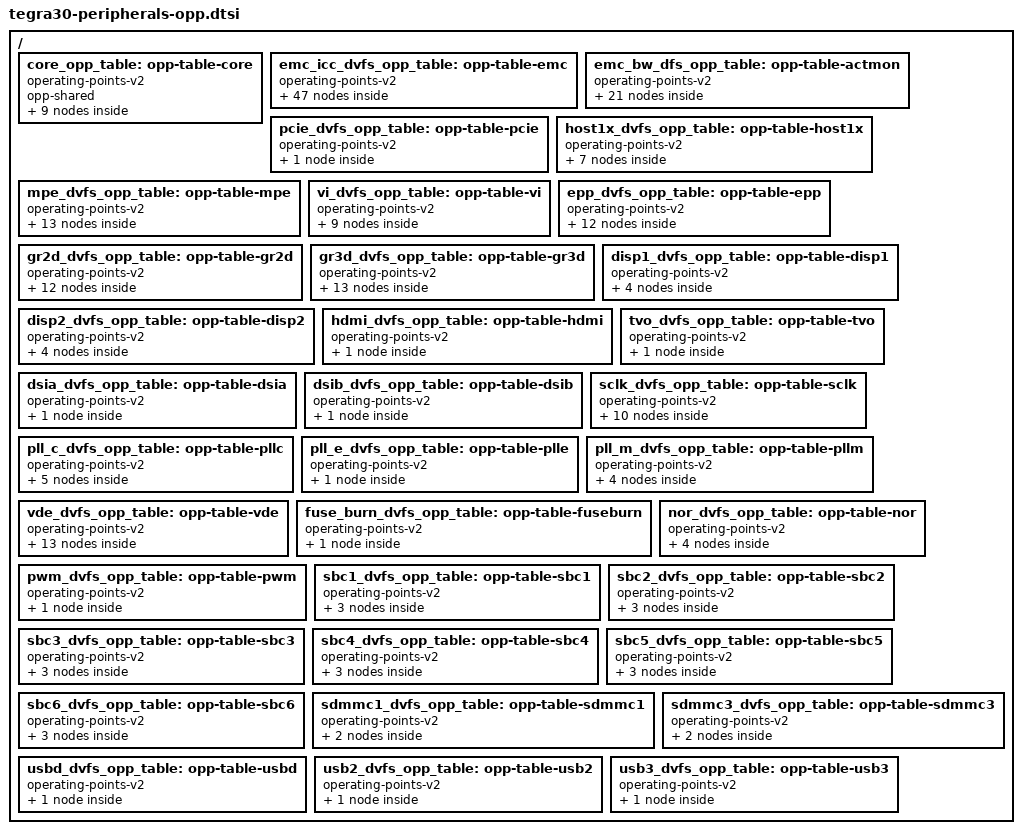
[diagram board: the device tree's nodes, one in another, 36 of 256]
// SPDX-License-Identifier: GPL-2.0

/ {
	core_opp_table: opp-table-core {
		compatible = "operating-points-v2";
		opp-shared;

		core_opp_950: opp-950000 {
			opp-microvolt = <950000 950000 1350000>;
			opp-level = <950000>;
		};

		core_opp_1000: opp-1000000 {
			opp-microvolt = <1000000 1000000 1350000>;
			opp-level = <1000000>;
		};

		core_opp_1050: opp-1050000 {
			opp-microvolt = <1050000 1050000 1350000>;
			opp-level = <1050000>;
		};

		core_opp_1100: opp-1100000 {
			opp-microvolt = <1100000 1100000 1350000>;
			opp-level = <1100000>;
		};

		core_opp_1150: opp-1150000 {
			opp-microvolt = <1150000 1150000 1350000>;
			opp-level = <1150000>;
		};

		core_opp_1200: opp-1200000 {
			opp-microvolt = <1200000 1200000 1350000>;
			opp-level = <1200000>;
		};

		core_opp_1250: opp-1250000 {
			opp-microvolt = <1250000 1250000 1350000>;
			opp-level = <1250000>;
		};

		core_opp_1300: opp-1300000 {
			opp-microvolt = <1300000 1300000 1350000>;
			opp-level = <1300000>;
		};

		core_opp_1350: opp-1350000 {
			opp-microvolt = <1350000 1350000 1350000>;
			opp-level = <1350000>;
		};
	};

	emc_icc_dvfs_opp_table: opp-table-emc {
		compatible = "operating-points-v2";

		opp-12750000-950 {
			opp-microvolt = <950000 950000 1350000>;
			opp-hz = /bits/ 64 <12750000>;
			opp-supported-hw = <0x0006>;
			required-opps = <&core_opp_950>;
		};

		opp-12750000-1000 {
			opp-microvolt = <1000000 1000000 1350000>;
			opp-hz = /bits/ 64 <12750000>;
			opp-supported-hw = <0x0001>;
			required-opps = <&core_opp_1000>;
		};

		opp-12750000-1250 {
			opp-microvolt = <1250000 1250000 1350000>;
			opp-hz = /bits/ 64 <12750000>;
			opp-supported-hw = <0x0008>;
			required-opps = <&core_opp_1250>;
		};

		opp-25500000-950 {
			opp-microvolt = <950000 950000 1350000>;
			opp-hz = /bits/ 64 <25500000>;
			opp-supported-hw = <0x0006>;
			required-opps = <&core_opp_950>;
		};

		opp-25500000-1000 {
			opp-microvolt = <1000000 1000000 1350000>;
			opp-hz = /bits/ 64 <25500000>;
			opp-supported-hw = <0x0001>;
			required-opps = <&core_opp_1000>;
		};

		opp-25500000-1250 {
			opp-microvolt = <1250000 1250000 1350000>;
			opp-hz = /bits/ 64 <25500000>;
			opp-supported-hw = <0x0008>;
			required-opps = <&core_opp_1250>;
		};

		opp-27000000-950 {
			opp-microvolt = <950000 950000 1350000>;
			opp-hz = /bits/ 64 <27000000>;
			opp-supported-hw = <0x0006>;
			required-opps = <&core_opp_950>;
		};

		opp-27000000-1000 {
			opp-microvolt = <1000000 1000000 1350000>;
			opp-hz = /bits/ 64 <27000000>;
			opp-supported-hw = <0x0001>;
			required-opps = <&core_opp_1000>;
		};

		opp-27000000-1250 {
			opp-microvolt = <1250000 1250000 1350000>;
			opp-hz = /bits/ 64 <27000000>;
			opp-supported-hw = <0x0008>;
			required-opps = <&core_opp_1250>;
		};

		opp-51000000-950 {
			opp-microvolt = <950000 950000 1350000>;
			opp-hz = /bits/ 64 <51000000>;
			opp-supported-hw = <0x0006>;
			required-opps = <&core_opp_950>;
		};

		opp-51000000-1000 {
			opp-microvolt = <1000000 1000000 1350000>;
			opp-hz = /bits/ 64 <51000000>;
			opp-supported-hw = <0x0001>;
			required-opps = <&core_opp_1000>;
		};

		opp-51000000-1250 {
			opp-microvolt = <1250000 1250000 1350000>;
			opp-hz = /bits/ 64 <51000000>;
			opp-supported-hw = <0x0008>;
			required-opps = <&core_opp_1250>;
		};

		opp-54000000-950 {
			opp-microvolt = <950000 950000 1350000>;
			opp-hz = /bits/ 64 <54000000>;
			opp-supported-hw = <0x0006>;
			required-opps = <&core_opp_950>;
		};

		opp-54000000-1000 {
			opp-microvolt = <1000000 1000000 1350000>;
			opp-hz = /bits/ 64 <54000000>;
			opp-supported-hw = <0x0001>;
			required-opps = <&core_opp_1000>;
		};

		opp-54000000-1250 {
			opp-microvolt = <1250000 1250000 1350000>;
			opp-hz = /bits/ 64 <54000000>;
			opp-supported-hw = <0x0008>;
			required-opps = <&core_opp_1250>;
		};

		opp-102000000-950 {
			opp-microvolt = <950000 950000 1350000>;
			opp-hz = /bits/ 64 <102000000>;
			opp-supported-hw = <0x0006>;
			required-opps = <&core_opp_950>;
		};

		opp-102000000-1000 {
			opp-microvolt = <1000000 1000000 1350000>;
			opp-hz = /bits/ 64 <102000000>;
			opp-supported-hw = <0x0001>;
			required-opps = <&core_opp_1000>;
		};

		opp-102000000-1250 {
			opp-microvolt = <1250000 1250000 1350000>;
			opp-hz = /bits/ 64 <102000000>;
			opp-supported-hw = <0x0008>;
			required-opps = <&core_opp_1250>;
		};

		opp-108000000-1000 {
			opp-microvolt = <1000000 1000000 1350000>;
			opp-hz = /bits/ 64 <108000000>;
			opp-supported-hw = <0x0007>;
			required-opps = <&core_opp_1000>;
		};

		opp-108000000-1250 {
			opp-microvolt = <1250000 1250000 1350000>;
			opp-hz = /bits/ 64 <108000000>;
			opp-supported-hw = <0x0008>;
			required-opps = <&core_opp_1250>;
		};

		opp-204000000-1000 {
			opp-microvolt = <1000000 1000000 1350000>;
			opp-hz = /bits/ 64 <204000000>;
			opp-supported-hw = <0x0007>;
			required-opps = <&core_opp_1000>;
			opp-suspend;
		};

		opp-204000000-1250 {
			opp-microvolt = <1250000 1250000 1350000>;
			opp-hz = /bits/ 64 <204000000>;
			opp-supported-hw = <0x0008>;
			required-opps = <&core_opp_1250>;
			opp-suspend;
		};

		opp-266500000-1000 {
			opp-microvolt = <1000000 1000000 1350000>;
			opp-hz = /bits/ 64 <266500000>;
			opp-supported-hw = <0x0007>;
			required-opps = <&core_opp_1000>;
		};

		opp-266500000-1250 {
			opp-microvolt = <1250000 1250000 1350000>;
			opp-hz = /bits/ 64 <266500000>;
			opp-supported-hw = <0x0008>;
			required-opps = <&core_opp_1250>;
		};

		opp-333500000-1000 {
			opp-microvolt = <1000000 1000000 1350000>;
			opp-hz = /bits/ 64 <333500000>;
			opp-supported-hw = <0x0006>;
			required-opps = <&core_opp_1000>;
		};

		opp-333500000-1200 {
			opp-microvolt = <1200000 1200000 1350000>;
			opp-hz = /bits/ 64 <333500000>;
			opp-supported-hw = <0x0001>;
			required-opps = <&core_opp_1200>;
		};

		opp-333500000-1250 {
			opp-microvolt = <1250000 1250000 1350000>;
			opp-hz = /bits/ 64 <333500000>;
			opp-supported-hw = <0x0008>;
			required-opps = <&core_opp_1250>;
		};

		opp-375000000-1000 {
			opp-microvolt = <1000000 1000000 1350000>;
			opp-hz = /bits/ 64 <375000000>;
			opp-supported-hw = <0x0006>;
			required-opps = <&core_opp_1000>;
		};

		opp-375000000-1200 {
			opp-microvolt = <1200000 1200000 1350000>;
			opp-hz = /bits/ 64 <375000000>;
			opp-supported-hw = <0x0001>;
			required-opps = <&core_opp_1200>;
		};

		opp-375000000-1250 {
			opp-microvolt = <1250000 1250000 1350000>;
			opp-hz = /bits/ 64 <375000000>;
			opp-supported-hw = <0x0008>;
			required-opps = <&core_opp_1250>;
		};

		opp-400000000-1000 {
			opp-microvolt = <1000000 1000000 1350000>;
			opp-hz = /bits/ 64 <400000000>;
			opp-supported-hw = <0x0006>;
			required-opps = <&core_opp_1000>;
		};

		opp-400000000-1200 {
			opp-microvolt = <1200000 1200000 1350000>;
			opp-hz = /bits/ 64 <400000000>;
			opp-supported-hw = <0x0001>;
			required-opps = <&core_opp_1200>;
		};

		opp-400000000-1250 {
			opp-microvolt = <1250000 1250000 1350000>;
			opp-hz = /bits/ 64 <400000000>;
			opp-supported-hw = <0x0008>;
			required-opps = <&core_opp_1250>;
		};

		opp-416000000-1200 {
			opp-microvolt = <1200000 1200000 1350000>;
			opp-hz = /bits/ 64 <416000000>;
			opp-supported-hw = <0x0007>;
			required-opps = <&core_opp_1200>;
		};

		opp-416000000-1250 {
			opp-microvolt = <1250000 1250000 1350000>;
			opp-hz = /bits/ 64 <416000000>;
			opp-supported-hw = <0x0008>;
			required-opps = <&core_opp_1250>;
		};

		opp-450000000-1200 {
			opp-microvolt = <1200000 1200000 1350000>;
			opp-hz = /bits/ 64 <450000000>;
			opp-supported-hw = <0x0007>;
			required-opps = <&core_opp_1200>;
		};

		opp-450000000-1250 {
			opp-microvolt = <1250000 1250000 1350000>;
			opp-hz = /bits/ 64 <450000000>;
			opp-supported-hw = <0x0008>;
			required-opps = <&core_opp_1250>;
		};

		opp-500000000-1200 {
			opp-microvolt = <1200000 1200000 1350000>;
			opp-hz = /bits/ 64 <500000000>;
			opp-supported-hw = <0x0007>;
			required-opps = <&core_opp_1200>;
		};

		opp-500000000-1250 {
			opp-microvolt = <1250000 1250000 1350000>;
			opp-hz = /bits/ 64 <500000000>;
			opp-supported-hw = <0x0008>;
			required-opps = <&core_opp_1250>;
		};

		opp-533000000-1200 {
			opp-microvolt = <1200000 1200000 1350000>;
			opp-hz = /bits/ 64 <533000000>;
			opp-supported-hw = <0x0007>;
			required-opps = <&core_opp_1200>;
		};

		opp-533000000-1250 {
			opp-microvolt = <1250000 1250000 1350000>;
			opp-hz = /bits/ 64 <533000000>;
			opp-supported-hw = <0x0008>;
			required-opps = <&core_opp_1250>;
		};

		opp-625000000-1200 {
			opp-microvolt = <1200000 1200000 1350000>;
			opp-hz = /bits/ 64 <625000000>;
			opp-supported-hw = <0x0006>;
			required-opps = <&core_opp_1200>;
		};

		opp-625000000-1250 {
			opp-microvolt = <1250000 1250000 1350000>;
			opp-hz = /bits/ 64 <625000000>;
			opp-supported-hw = <0x0008>;
			required-opps = <&core_opp_1250>;
		};

		opp-667000000-1200 {
			opp-microvolt = <1200000 1200000 1350000>;
			opp-hz = /bits/ 64 <667000000>;
			opp-supported-hw = <0x0006>;
			required-opps = <&core_opp_1200>;
		};

		opp-750000000-1300 {
			opp-microvolt = <1300000 1300000 1350000>;
			opp-hz = /bits/ 64 <750000000>;
			opp-supported-hw = <0x0004>;
			required-opps = <&core_opp_1300>;
		};

		opp-800000000-1300 {
			opp-microvolt = <1300000 1300000 1350000>;
			opp-hz = /bits/ 64 <800000000>;
			opp-supported-hw = <0x0004>;
			required-opps = <&core_opp_1300>;
		};

		opp-900000000-1350 {
			opp-microvolt = <1350000 1350000 1350000>;
			opp-hz = /bits/ 64 <900000000>;
			opp-supported-hw = <0x0004>;
			required-opps = <&core_opp_1350>;
		};
	};

	emc_bw_dfs_opp_table: opp-table-actmon {
		compatible = "operating-points-v2";

		opp-12750000 {
			opp-hz = /bits/ 64 <12750000>;
			opp-supported-hw = <0x000F>;
			opp-peak-kBps = <102000>;
		};

		opp-25500000 {
			opp-hz = /bits/ 64 <25500000>;
			opp-supported-hw = <0x000F>;
			opp-peak-kBps = <204000>;
		};

		opp-27000000 {
			opp-hz = /bits/ 64 <27000000>;
			opp-supported-hw = <0x000F>;
			opp-peak-kBps = <216000>;
		};

		opp-51000000 {
			opp-hz = /bits/ 64 <51000000>;
			opp-supported-hw = <0x000F>;
			opp-peak-kBps = <408000>;
		};

		opp-54000000 {
			opp-hz = /bits/ 64 <54000000>;
			opp-supported-hw = <0x000F>;
			opp-peak-kBps = <432000>;
		};

		opp-102000000 {
			opp-hz = /bits/ 64 <102000000>;
			opp-supported-hw = <0x000F>;
			opp-peak-kBps = <816000>;
		};

		opp-108000000 {
			opp-hz = /bits/ 64 <108000000>;
			opp-supported-hw = <0x000F>;
			opp-peak-kBps = <864000>;
		};

		opp-204000000 {
			opp-hz = /bits/ 64 <204000000>;
			opp-supported-hw = <0x000F>;
			opp-peak-kBps = <1632000>;
			opp-suspend;
		};

		opp-266500000 {
			opp-hz = /bits/ 64 <266500000>;
			opp-supported-hw = <0x000F>;
			opp-peak-kBps = <2132000>;
		};

		opp-333500000 {
			opp-hz = /bits/ 64 <333500000>;
			opp-supported-hw = <0x000F>;
			opp-peak-kBps = <2668000>;
		};

		opp-375000000 {
			opp-hz = /bits/ 64 <375000000>;
			opp-supported-hw = <0x000F>;
			opp-peak-kBps = <3000000>;
		};

		opp-400000000 {
			opp-hz = /bits/ 64 <400000000>;
			opp-supported-hw = <0x000F>;
			opp-peak-kBps = <3200000>;
		};

		opp-416000000 {
			opp-hz = /bits/ 64 <416000000>;
			opp-supported-hw = <0x000F>;
			opp-peak-kBps = <3328000>;
		};

		opp-450000000 {
			opp-hz = /bits/ 64 <450000000>;
			opp-supported-hw = <0x000F>;
			opp-peak-kBps = <3600000>;
		};

		opp-500000000 {
			opp-hz = /bits/ 64 <500000000>;
			opp-supported-hw = <0x000F>;
			opp-peak-kBps = <4000000>;
		};

		opp-533000000 {
			opp-hz = /bits/ 64 <533000000>;
			opp-supported-hw = <0x000F>;
			opp-peak-kBps = <4264000>;
		};

		opp-625000000 {
			opp-hz = /bits/ 64 <625000000>;
			opp-supported-hw = <0x000E>;
			opp-peak-kBps = <5000000>;
		};

		opp-667000000 {
			opp-hz = /bits/ 64 <667000000>;
			opp-supported-hw = <0x0006>;
			opp-peak-kBps = <5336000>;
		};

		opp-750000000 {
			opp-hz = /bits/ 64 <750000000>;
			opp-supported-hw = <0x0004>;
			opp-peak-kBps = <6000000>;
		};

		opp-800000000 {
			opp-hz = /bits/ 64 <800000000>;
			opp-supported-hw = <0x0004>;
			opp-peak-kBps = <6400000>;
		};

		opp-900000000 {
			opp-hz = /bits/ 64 <900000000>;
			opp-supported-hw = <0x0004>;
			opp-peak-kBps = <7200000>;
		};
	};

	pcie_dvfs_opp_table: opp-table-pcie {
		compatible = "operating-points-v2";

		opp-250000000-1000 {
			opp-microvolt = <1000000 1000000 1350000>;
			opp-hz = /bits/ 64 <250000000>;
			opp-supported-hw = <0x000F>;
			required-opps = <&core_opp_1000>;
		};
	};

	host1x_dvfs_opp_table: opp-table-host1x {
		compatible = "operating-points-v2";

		opp-152000000-1000 {
			opp-microvolt = <1000000 1000000 1350000>;
			opp-hz = /bits/ 64 <152000000>;
			opp-supported-hw = <0x0007>;
			required-opps = <&core_opp_1000>;
		};

		opp-188000000-1050 {
			opp-microvolt = <1050000 1050000 1350000>;
			opp-hz = /bits/ 64 <188000000>;
			opp-supported-hw = <0x0007>;
			required-opps = <&core_opp_1050>;
		};

		opp-222000000-1100 {
			opp-microvolt = <1100000 1100000 1350000>;
			opp-hz = /bits/ 64 <222000000>;
			opp-supported-hw = <0x0007>;
			required-opps = <&core_opp_1100>;
		};

		opp-242000000-1250 {
			opp-microvolt = <1250000 1250000 1350000>;
			opp-hz = /bits/ 64 <242000000>;
			opp-supported-hw = <0x0008>;
			required-opps = <&core_opp_1250>;
		};

		opp-254000000-1150 {
			opp-microvolt = <1150000 1150000 1350000>;
			opp-hz = /bits/ 64 <254000000>;
			opp-supported-hw = <0x0007>;
			required-opps = <&core_opp_1150>;
		};

		opp-267000000-1200 {
			opp-microvolt = <1200000 1200000 1350000>;
			opp-hz = /bits/ 64 <267000000>;
			opp-supported-hw = <0x0007>;
			required-opps = <&core_opp_1200>;
		};

		opp-300000000-1350 {
			opp-microvolt = <1350000 1350000 1350000>;
			opp-hz = /bits/ 64 <300000000>;
			opp-supported-hw = <0x0004>;
			required-opps = <&core_opp_1350>;
		};
	};

	mpe_dvfs_opp_table: opp-table-mpe {
		compatible = "operating-points-v2";

		opp-234000000-1000 {
			opp-microvolt = <1000000 1000000 1350000>;
			opp-hz = /bits/ 64 <234000000>;
			opp-supported-hw = <0x0003>;
			required-opps = <&core_opp_1000>;
		};

		opp-247000000-1000 {
			opp-microvolt = <1000000 1000000 1350000>;
			opp-hz = /bits/ 64 <247000000>;
			opp-supported-hw = <0x0004>;
			required-opps = <&core_opp_1000>;
		};

		opp-285000000-1050 {
			opp-microvolt = <1050000 1050000 1350000>;
			opp-hz = /bits/ 64 <285000000>;
			opp-supported-hw = <0x0003>;
			required-opps = <&core_opp_1050>;
		};

		opp-304000000-1050 {
			opp-microvolt = <1050000 1050000 1350000>;
			opp-hz = /bits/ 64 <304000000>;
			opp-supported-hw = <0x0004>;
			required-opps = <&core_opp_1050>;
		};

		opp-332000000-1100 {
			opp-microvolt = <1100000 1100000 1350000>;
			opp-hz = /bits/ 64 <332000000>;
			opp-supported-hw = <0x0003>;
			required-opps = <&core_opp_1100>;
		};

		opp-361000000-1100 {
			opp-microvolt = <1100000 1100000 1350000>;
			opp-hz = /bits/ 64 <361000000>;
			opp-supported-hw = <0x0004>;
			required-opps = <&core_opp_1100>;
		};

		opp-380000000-1150 {
			opp-microvolt = <1150000 1150000 1350000>;
			opp-hz = /bits/ 64 <380000000>;
			opp-supported-hw = <0x0003>;
			required-opps = <&core_opp_1150>;
		};

		opp-408000000-1150 {
			opp-microvolt = <1150000 1150000 1350000>;
			opp-hz = /bits/ 64 <408000000>;
			opp-supported-hw = <0x0004>;
			required-opps = <&core_opp_1150>;
		};

		opp-416000000-1200 {
			opp-microvolt = <1200000 1200000 1350000>;
			opp-hz = /bits/ 64 <416000000>;
			opp-supported-hw = <0x0003>;
			required-opps = <&core_opp_1200>;
		};

		opp-446000000-1200 {
			opp-microvolt = <1200000 1200000 1350000>;
			opp-hz = /bits/ 64 <446000000>;
			opp-supported-hw = <0x0004>;
			required-opps = <&core_opp_1200>;
		};

		opp-484000000-1250 {
			opp-microvolt = <1250000 1250000 1350000>;
			opp-hz = /bits/ 64 <484000000>;
			opp-supported-hw = <0x000C>;
			required-opps = <&core_opp_1250>;
		};

		opp-520000000-1300 {
			opp-microvolt = <1300000 1300000 1350000>;
			opp-hz = /bits/ 64 <520000000>;
			opp-supported-hw = <0x0004>;
			required-opps = <&core_opp_1300>;
		};

		opp-600000000-1350 {
			opp-microvolt = <1350000 1350000 1350000>;
			opp-hz = /bits/ 64 <600000000>;
			opp-supported-hw = <0x0004>;
			required-opps = <&core_opp_1350>;
		};
	};

	vi_dvfs_opp_table: opp-table-vi {
		compatible = "operating-points-v2";

		opp-216000000-1000 {
			opp-microvolt = <1000000 1000000 1350000>;
			opp-hz = /bits/ 64 <216000000>;
			opp-supported-hw = <0x0003>;
			required-opps = <&core_opp_1000>;
		};

		opp-219000000-1000 {
			opp-microvolt = <1000000 1000000 1350000>;
			opp-hz = /bits/ 64 <219000000>;
			opp-supported-hw = <0x0004>;
			required-opps = <&core_opp_1000>;
		};

		opp-267000000-1050 {
			opp-microvolt = <1050000 1050000 1350000>;
			opp-hz = /bits/ 64 <267000000>;
			opp-supported-hw = <0x0006>;
			required-opps = <&core_opp_1050>;
		};

		opp-285000000-1050 {
			opp-microvolt = <1050000 1050000 1350000>;
			opp-hz = /bits/ 64 <285000000>;
			opp-supported-hw = <0x0001>;
			required-opps = <&core_opp_1050>;
		};

		opp-300000000-1100 {
			opp-microvolt = <1100000 1100000 1350000>;
			opp-hz = /bits/ 64 <300000000>;
			opp-supported-hw = <0x0007>;
			required-opps = <&core_opp_1100>;
		};

		opp-371000000-1150 {
			opp-microvolt = <1150000 1150000 1350000>;
			opp-hz = /bits/ 64 <371000000>;
			opp-supported-hw = <0x0006>;
			required-opps = <&core_opp_1150>;
		};

		opp-409000000-1200 {
			opp-microvolt = <1200000 1200000 1350000>;
			opp-hz = /bits/ 64 <409000000>;
			opp-supported-hw = <0x0006>;
			required-opps = <&core_opp_1200>;
		};

		opp-425000000-1250 {
			opp-microvolt = <1250000 1250000 1350000>;
			opp-hz = /bits/ 64 <425000000>;
			opp-supported-hw = <0x0004>;
			required-opps = <&core_opp_1250>;
		};

		opp-470000000-1250 {
			opp-microvolt = <1250000 1250000 1350000>;
			opp-hz = /bits/ 64 <470000000>;
			opp-supported-hw = <0x0008>;
			required-opps = <&core_opp_1250>;
		};
	};

	epp_dvfs_opp_table: opp-table-epp {
		compatible = "operating-points-v2";

		opp-267000000-1000 {
			opp-microvolt = <1000000 1000000 1350000>;
			opp-hz = /bits/ 64 <267000000>;
			opp-supported-hw = <0x0007>;
			required-opps = <&core_opp_1000>;
		};

		opp-285000000-1050 {
			opp-microvolt = <1050000 1050000 1350000>;
			opp-hz = /bits/ 64 <285000000>;
			opp-supported-hw = <0x0003>;
			required-opps = <&core_opp_1050>;
		};

		opp-304000000-1050 {
			opp-microvolt = <1050000 1050000 1350000>;
			opp-hz = /bits/ 64 <304000000>;
			opp-supported-hw = <0x0004>;
			required-opps = <&core_opp_1050>;
		};

		opp-332000000-1100 {
			opp-microvolt = <1100000 1100000 1350000>;
			opp-hz = /bits/ 64 <332000000>;
			opp-supported-hw = <0x0003>;
			required-opps = <&core_opp_1100>;
		};

		opp-361000000-1100 {
			opp-microvolt = <1100000 1100000 1350000>;
			opp-hz = /bits/ 64 <361000000>;
			opp-supported-hw = <0x0004>;
			required-opps = <&core_opp_1100>;
		};

		opp-380000000-1150 {
			opp-microvolt = <1150000 1150000 1350000>;
			opp-hz = /bits/ 64 <380000000>;
			opp-supported-hw = <0x0003>;
			required-opps = <&core_opp_1150>;
		};

		opp-408000000-1150 {
			opp-microvolt = <1150000 1150000 1350000>;
			opp-hz = /bits/ 64 <408000000>;
			opp-supported-hw = <0x0004>;
			required-opps = <&core_opp_1150>;
		};

		opp-416000000-1200 {
			opp-microvolt = <1200000 1200000 1350000>;
			opp-hz = /bits/ 64 <416000000>;
			opp-supported-hw = <0x0003>;
			required-opps = <&core_opp_1200>;
		};

		opp-446000000-1200 {
			opp-microvolt = <1200000 1200000 1350000>;
			opp-hz = /bits/ 64 <446000000>;
			opp-supported-hw = <0x0004>;
			required-opps = <&core_opp_1200>;
		};

		opp-484000000-1250 {
			opp-microvolt = <1250000 1250000 1350000>;
			opp-hz = /bits/ 64 <484000000>;
			opp-supported-hw = <0x000C>;
			required-opps = <&core_opp_1250>;
		};

		opp-520000000-1300 {
			opp-microvolt = <1300000 1300000 1350000>;
			opp-hz = /bits/ 64 <520000000>;
			opp-supported-hw = <0x0004>;
			required-opps = <&core_opp_1300>;
		};

		opp-600000000-1350 {
			opp-microvolt = <1350000 1350000 1350000>;
			opp-hz = /bits/ 64 <600000000>;
			opp-supported-hw = <0x0004>;
			required-opps = <&core_opp_1350>;
		};
	};

	gr2d_dvfs_opp_table: opp-table-gr2d {
		compatible = "operating-points-v2";

		opp-267000000-1000 {
			opp-microvolt = <1000000 1000000 1350000>;
			opp-hz = /bits/ 64 <267000000>;
			opp-supported-hw = <0x0007>;
			required-opps = <&core_opp_1000>;
		};

		opp-285000000-1050 {
			opp-microvolt = <1050000 1050000 1350000>;
			opp-hz = /bits/ 64 <285000000>;
			opp-supported-hw = <0x0003>;
			required-opps = <&core_opp_1050>;
		};

		opp-304000000-1050 {
			opp-microvolt = <1050000 1050000 1350000>;
			opp-hz = /bits/ 64 <304000000>;
			opp-supported-hw = <0x0004>;
			required-opps = <&core_opp_1050>;
		};

		opp-332000000-1100 {
			opp-microvolt = <1100000 1100000 1350000>;
			opp-hz = /bits/ 64 <332000000>;
			opp-supported-hw = <0x0003>;
			required-opps = <&core_opp_1100>;
		};

		opp-361000000-1100 {
			opp-microvolt = <1100000 1100000 1350000>;
			opp-hz = /bits/ 64 <361000000>;
			opp-supported-hw = <0x0004>;
			required-opps = <&core_opp_1100>;
		};

		opp-380000000-1150 {
			opp-microvolt = <1150000 1150000 1350000>;
			opp-hz = /bits/ 64 <380000000>;
			opp-supported-hw = <0x0003>;
			required-opps = <&core_opp_1150>;
		};

		opp-408000000-1150 {
			opp-microvolt = <1150000 1150000 1350000>;
			opp-hz = /bits/ 64 <408000000>;
			opp-supported-hw = <0x0004>;
			required-opps = <&core_opp_1150>;
		};

		opp-416000000-1200 {
			opp-microvolt = <1200000 1200000 1350000>;
			opp-hz = /bits/ 64 <416000000>;
			opp-supported-hw = <0x0003>;
			required-opps = <&core_opp_1200>;
		};

		opp-446000000-1200 {
			opp-microvolt = <1200000 1200000 1350000>;
			opp-hz = /bits/ 64 <446000000>;
			opp-supported-hw = <0x0004>;
			required-opps = <&core_opp_1200>;
		};

		opp-484000000-1250 {
			opp-microvolt = <1250000 1250000 1350000>;
			opp-hz = /bits/ 64 <484000000>;
			opp-supported-hw = <0x000C>;
			required-opps = <&core_opp_1250>;
		};

		opp-520000000-1300 {
			opp-microvolt = <1300000 1300000 1350000>;
			opp-hz = /bits/ 64 <520000000>;
			opp-supported-hw = <0x0004>;
			required-opps = <&core_opp_1300>;
		};

		opp-600000000-1350 {
			opp-microvolt = <1350000 1350000 1350000>;
			opp-hz = /bits/ 64 <600000000>;
			opp-supported-hw = <0x0004>;
			required-opps = <&core_opp_1350>;
		};
	};

	gr3d_dvfs_opp_table: opp-table-gr3d {
		compatible = "operating-points-v2";

		opp-234000000-1000 {
			opp-microvolt = <1000000 1000000 1350000>;
			opp-hz = /bits/ 64 <234000000>;
			opp-supported-hw = <0x0003>;
			required-opps = <&core_opp_1000>, <&core_opp_1000>;
		};

		opp-247000000-1000 {
			opp-microvolt = <1000000 1000000 1350000>;
			opp-hz = /bits/ 64 <247000000>;
			opp-supported-hw = <0x0004>;
			required-opps = <&core_opp_1000>, <&core_opp_1000>;
		};

		opp-285000000-1050 {
			opp-microvolt = <1050000 1050000 1350000>;
			opp-hz = /bits/ 64 <285000000>;
			opp-supported-hw = <0x0003>;
			required-opps = <&core_opp_1050>, <&core_opp_1050>;
		};

		opp-304000000-1050 {
			opp-microvolt = <1050000 1050000 1350000>;
			opp-hz = /bits/ 64 <304000000>;
			opp-supported-hw = <0x0004>;
			required-opps = <&core_opp_1050>, <&core_opp_1050>;
		};

		opp-332000000-1100 {
			opp-microvolt = <1100000 1100000 1350000>;
			opp-hz = /bits/ 64 <332000000>;
			opp-supported-hw = <0x0003>;
			required-opps = <&core_opp_1100>, <&core_opp_1100>;
		};

		opp-361000000-1100 {
			opp-microvolt = <1100000 1100000 1350000>;
			opp-hz = /bits/ 64 <361000000>;
			opp-supported-hw = <0x0004>;
			required-opps = <&core_opp_1100>, <&core_opp_1100>;
		};

		opp-380000000-1150 {
			opp-microvolt = <1150000 1150000 1350000>;
			opp-hz = /bits/ 64 <380000000>;
			opp-supported-hw = <0x0003>;
			required-opps = <&core_opp_1150>, <&core_opp_1150>;
		};

		opp-408000000-1150 {
			opp-microvolt = <1150000 1150000 1350000>;
			opp-hz = /bits/ 64 <408000000>;
			opp-supported-hw = <0x0004>;
			required-opps = <&core_opp_1150>, <&core_opp_1150>;
		};

		opp-416000000-1200 {
			opp-microvolt = <1200000 1200000 1350000>;
			opp-hz = /bits/ 64 <416000000>;
			opp-supported-hw = <0x0003>;
			required-opps = <&core_opp_1200>, <&core_opp_1200>;
		};

		opp-446000000-1200 {
			opp-microvolt = <1200000 1200000 1350000>;
			opp-hz = /bits/ 64 <446000000>;
			opp-supported-hw = <0x0004>;
			required-opps = <&core_opp_1200>, <&core_opp_1200>;
		};

		opp-484000000-1250 {
			opp-microvolt = <1250000 1250000 1350000>;
			opp-hz = /bits/ 64 <484000000>;
			opp-supported-hw = <0x000C>;
			required-opps = <&core_opp_1250>, <&core_opp_1250>;
		};

		opp-520000000-1300 {
			opp-microvolt = <1300000 1300000 1350000>;
			opp-hz = /bits/ 64 <520000000>;
			opp-supported-hw = <0x0004>;
			required-opps = <&core_opp_1300>, <&core_opp_1300>;
		};

		opp-600000000-1350 {
			opp-microvolt = <1350000 1350000 1350000>;
			opp-hz = /bits/ 64 <600000000>;
			opp-supported-hw = <0x0004>;
			required-opps = <&core_opp_1350>, <&core_opp_1350>;
		};
	};

	disp1_dvfs_opp_table: opp-table-disp1 {
		compatible = "operating-points-v2";

		opp-120000000-1000 {
			opp-microvolt = <1000000 1000000 1350000>;
			opp-hz = /bits/ 64 <120000000>;
			opp-supported-hw = <0x0009>;
			required-opps = <&core_opp_1000>;
		};

		opp-155000000-1000 {
			opp-microvolt = <1000000 1000000 1350000>;
			opp-hz = /bits/ 64 <155000000>;
			opp-supported-hw = <0x0006>;
			required-opps = <&core_opp_1000>;
		};

		opp-190000000-1200 {
			opp-microvolt = <1200000 1200000 1350000>;
			opp-hz = /bits/ 64 <190000000>;
			opp-supported-hw = <0x0009>;
			required-opps = <&core_opp_1200>;
		};

		opp-268000000-1050 {
			opp-microvolt = <1050000 1050000 1350000>;
			opp-hz = /bits/ 64 <268000000>;
			opp-supported-hw = <0x0006>;
			required-opps = <&core_opp_1050>;
		};
	};

	disp2_dvfs_opp_table: opp-table-disp2 {
		compatible = "operating-points-v2";

		opp-120000000-1000 {
			opp-microvolt = <1000000 1000000 1350000>;
			opp-hz = /bits/ 64 <120000000>;
			opp-supported-hw = <0x0009>;
			required-opps = <&core_opp_1000>;
		};

		opp-155000000-1000 {
			opp-microvolt = <1000000 1000000 1350000>;
			opp-hz = /bits/ 64 <155000000>;
			opp-supported-hw = <0x0006>;
			required-opps = <&core_opp_1000>;
		};

		opp-190000000-1200 {
			opp-microvolt = <1200000 1200000 1350000>;
			opp-hz = /bits/ 64 <190000000>;
			opp-supported-hw = <0x0009>;
			required-opps = <&core_opp_1200>;
		};

		opp-268000000-1050 {
			opp-microvolt = <1050000 1050000 1350000>;
			opp-hz = /bits/ 64 <268000000>;
			opp-supported-hw = <0x0006>;
			required-opps = <&core_opp_1050>;
		};
	};

	hdmi_dvfs_opp_table: opp-table-hdmi {
		compatible = "operating-points-v2";

		opp-148500000-1000 {
			opp-microvolt = <1000000 1000000 1350000>;
			opp-hz = /bits/ 64 <148500000>;
			opp-supported-hw = <0x000F>;
			required-opps = <&core_opp_1000>;
		};
	};

	tvo_dvfs_opp_table: opp-table-tvo {
		compatible = "operating-points-v2";

		opp-297000000-1050 {
			opp-microvolt = <1050000 1050000 1350000>;
			opp-hz = /bits/ 64 <297000000>;
			opp-supported-hw = <0x000F>;
			required-opps = <&core_opp_1050>;
		};
	};

	dsia_dvfs_opp_table: opp-table-dsia {
		compatible = "operating-points-v2";

		opp-275000000-1000 {
			opp-microvolt = <1000000 1000000 1350000>;
			opp-hz = /bits/ 64 <275000000>;
			opp-supported-hw = <0x000F>;
			required-opps = <&core_opp_1000>;
		};
	};

	dsib_dvfs_opp_table: opp-table-dsib {
		compatible = "operating-points-v2";

		opp-275000000-1000 {
			opp-microvolt = <1000000 1000000 1350000>;
			opp-hz = /bits/ 64 <275000000>;
			opp-supported-hw = <0x000F>;
			required-opps = <&core_opp_1000>;
		};
	};

	sclk_dvfs_opp_table: opp-table-sclk {
		compatible = "operating-points-v2";

		opp-51000000-950 {
			opp-microvolt = <950000 950000 1350000>;
			opp-hz = /bits/ 64 <51000000>;
			opp-supported-hw = <0x0006>;
			required-opps = <&core_opp_950>;
		};

		opp-136000000-1000 {
			opp-microvolt = <1000000 1000000 1350000>;
			opp-hz = /bits/ 64 <136000000>;
			opp-supported-hw = <0x0001>;
			required-opps = <&core_opp_1000>;
		};

		opp-164000000-1050 {
			opp-microvolt = <1050000 1050000 1350000>;
			opp-hz = /bits/ 64 <164000000>;
			opp-supported-hw = <0x0001>;
			required-opps = <&core_opp_1050>;
		};

		opp-191000000-1100 {
			opp-microvolt = <1100000 1100000 1350000>;
			opp-hz = /bits/ 64 <191000000>;
			opp-supported-hw = <0x0001>;
			required-opps = <&core_opp_1100>;
		};

		opp-205000000-1000 {
			opp-microvolt = <1000000 1000000 1350000>;
			opp-hz = /bits/ 64 <205000000>;
			opp-supported-hw = <0x0006>;
			required-opps = <&core_opp_1000>;
		};

		opp-216000000-1150 {
			opp-microvolt = <1150000 1150000 1350000>;
			opp-hz = /bits/ 64 <216000000>;
			opp-supported-hw = <0x0001>;
			required-opps = <&core_opp_1150>;
		};

		opp-227000000-1100 {
			opp-microvolt = <1100000 1100000 1350000>;
			opp-hz = /bits/ 64 <227000000>;
			opp-supported-hw = <0x0006>;
			required-opps = <&core_opp_1100>;
		};

		opp-267000000-1200 {
			opp-microvolt = <1200000 1200000 1350000>;
			opp-hz = /bits/ 64 <267000000>;
			opp-supported-hw = <0x0006>;
			required-opps = <&core_opp_1200>;
		};

		opp-334000000-1250 {
			opp-microvolt = <1250000 1250000 1350000>;
			opp-hz = /bits/ 64 <334000000>;
			opp-supported-hw = <0x0004>;
			required-opps = <&core_opp_1250>;
		};

		opp-378000000-1250 {
			opp-microvolt = <1250000 1250000 1350000>;
			opp-hz = /bits/ 64 <378000000>;
			opp-supported-hw = <0x0008>;
			required-opps = <&core_opp_1250>;
		};
	};

	pll_c_dvfs_opp_table: opp-table-pllc {
		compatible = "operating-points-v2";

		opp-533000000-950 {
			opp-microvolt = <950000 950000 1350000>;
			opp-hz = /bits/ 64 <533000000>;
			opp-supported-hw = <0x000F>;
			required-opps = <&core_opp_950>;
		};

		opp-667000000-1000 {
			opp-microvolt = <1000000 1000000 1350000>;
			opp-hz = /bits/ 64 <667000000>;
			opp-supported-hw = <0x000F>;
			required-opps = <&core_opp_1000>;
		};

		opp-800000000-1100 {
			opp-microvolt = <1100000 1100000 1350000>;
			opp-hz = /bits/ 64 <800000000>;
			opp-supported-hw = <0x000F>;
			required-opps = <&core_opp_1100>;
		};

		opp-1066000000-1200 {
			opp-microvolt = <1200000 1200000 1350000>;
			opp-hz = /bits/ 64 <1066000000>;
			opp-supported-hw = <0x000F>;
			required-opps = <&core_opp_1200>;
		};

		opp-1200000000-1350 {
			opp-microvolt = <1350000 1350000 1350000>;
			opp-hz = /bits/ 64 <1200000000>;
			opp-supported-hw = <0x000F>;
			required-opps = <&core_opp_1350>;
		};
	};

	pll_e_dvfs_opp_table: opp-table-plle {
		compatible = "operating-points-v2";

		opp-100000000-1000 {
			opp-microvolt = <1000000 1000000 1350000>;
			opp-hz = /bits/ 64 <100000000>;
			opp-supported-hw = <0x000F>;
			required-opps = <&core_opp_1000>;
		};
	};

	pll_m_dvfs_opp_table: opp-table-pllm {
		compatible = "operating-points-v2";

		opp-533000000-950 {
			opp-microvolt = <950000 950000 1350000>;
			opp-hz = /bits/ 64 <533000000>;
			opp-supported-hw = <0x000F>;
			required-opps = <&core_opp_950>;
		};

		opp-667000000-1000 {
			opp-microvolt = <1000000 1000000 1350000>;
			opp-hz = /bits/ 64 <667000000>;
			opp-supported-hw = <0x000F>;
			required-opps = <&core_opp_1000>;
		};

		opp-800000000-1100 {
			opp-microvolt = <1100000 1100000 1350000>;
			opp-hz = /bits/ 64 <800000000>;
			opp-supported-hw = <0x000F>;
			required-opps = <&core_opp_1100>;
		};

		opp-1066000000-1200 {
			opp-microvolt = <1200000 1200000 1350000>;
			opp-hz = /bits/ 64 <1066000000>;
			opp-supported-hw = <0x000F>;
			required-opps = <&core_opp_1200>;
		};
	};

	vde_dvfs_opp_table: opp-table-vde {
		compatible = "operating-points-v2";

		opp-228000000-1000 {
			opp-microvolt = <1000000 1000000 1350000>;
			opp-hz = /bits/ 64 <228000000>;
			opp-supported-hw = <0x0003>;
			required-opps = <&core_opp_1000>;
		};

		opp-247000000-1000 {
			opp-microvolt = <1000000 1000000 1350000>;
			opp-hz = /bits/ 64 <247000000>;
			opp-supported-hw = <0x0004>;
			required-opps = <&core_opp_1000>;
		};

		opp-275000000-1050 {
			opp-microvolt = <1050000 1050000 1350000>;
			opp-hz = /bits/ 64 <275000000>;
			opp-supported-hw = <0x0003>;
			required-opps = <&core_opp_1050>;
		};

		opp-304000000-1050 {
			opp-microvolt = <1050000 1050000 1350000>;
			opp-hz = /bits/ 64 <304000000>;
			opp-supported-hw = <0x0004>;
			required-opps = <&core_opp_1050>;
		};

		opp-332000000-1100 {
			opp-microvolt = <1100000 1100000 1350000>;
			opp-hz = /bits/ 64 <332000000>;
			opp-supported-hw = <0x0003>;
			required-opps = <&core_opp_1100>;
		};

		opp-352000000-1100 {
			opp-microvolt = <1100000 1100000 1350000>;
			opp-hz = /bits/ 64 <352000000>;
			opp-supported-hw = <0x0004>;
			required-opps = <&core_opp_1100>;
		};

		opp-380000000-1150 {
			opp-microvolt = <1150000 1150000 1350000>;
			opp-hz = /bits/ 64 <380000000>;
			opp-supported-hw = <0x0003>;
			required-opps = <&core_opp_1150>;
		};

		opp-400000000-1150 {
			opp-microvolt = <1150000 1150000 1350000>;
			opp-hz = /bits/ 64 <400000000>;
			opp-supported-hw = <0x0004>;
			required-opps = <&core_opp_1150>;
		};

		opp-416000000-1200 {
			opp-microvolt = <1200000 1200000 1350000>;
			opp-hz = /bits/ 64 <416000000>;
			opp-supported-hw = <0x0003>;
			required-opps = <&core_opp_1200>;
		};

		opp-437000000-1200 {
			opp-microvolt = <1200000 1200000 1350000>;
			opp-hz = /bits/ 64 <437000000>;
			opp-supported-hw = <0x0004>;
			required-opps = <&core_opp_1200>;
		};

		opp-484000000-1250 {
			opp-microvolt = <1250000 1250000 1350000>;
			opp-hz = /bits/ 64 <484000000>;
			opp-supported-hw = <0x000C>;
			required-opps = <&core_opp_1250>;
		};

		opp-520000000-1300 {
			opp-microvolt = <1300000 1300000 1350000>;
			opp-hz = /bits/ 64 <520000000>;
			opp-supported-hw = <0x0004>;
			required-opps = <&core_opp_1300>;
		};

		opp-600000000-1350 {
			opp-microvolt = <1350000 1350000 1350000>;
			opp-hz = /bits/ 64 <600000000>;
			opp-supported-hw = <0x0004>;
			required-opps = <&core_opp_1350>;
		};
	};

	fuse_burn_dvfs_opp_table: opp-table-fuseburn {
		compatible = "operating-points-v2";

		opp-26000000-1150 {
			opp-microvolt = <1150000 1150000 1350000>;
			opp-hz = /bits/ 64 <26000000>;
			opp-supported-hw = <0x000F>;
			required-opps = <&core_opp_1150>;
		};
	};

	nor_dvfs_opp_table: opp-table-nor {
		compatible = "operating-points-v2";

		opp-108000000-1250 {
			opp-microvolt = <1250000 1250000 1350000>;
			opp-hz = /bits/ 64 <108000000>;
			opp-supported-hw = <0x0008>;
			required-opps = <&core_opp_1250>;
		};

		opp-115000000-1000 {
			opp-microvolt = <1000000 1000000 1350000>;
			opp-hz = /bits/ 64 <115000000>;
			opp-supported-hw = <0x0007>;
			required-opps = <&core_opp_1000>;
		};

		opp-130000000-1050 {
			opp-microvolt = <1050000 1050000 1350000>;
			opp-hz = /bits/ 64 <130000000>;
			opp-supported-hw = <0x0007>;
			required-opps = <&core_opp_1050>;
		};

		opp-133000000-1150 {
			opp-microvolt = <1150000 1150000 1350000>;
			opp-hz = /bits/ 64 <133000000>;
			opp-supported-hw = <0x0007>;
			required-opps = <&core_opp_1150>;
		};
	};

	pwm_dvfs_opp_table: opp-table-pwm {
		compatible = "operating-points-v2";

		opp-408000000-1000 {
			opp-microvolt = <1000000 1000000 1350000>;
			opp-hz = /bits/ 64 <408000000>;
			opp-supported-hw = <0x000F>;
			required-opps = <&core_opp_1000>;
		};
	};

	sbc1_dvfs_opp_table: opp-table-sbc1 {
		compatible = "operating-points-v2";

		opp-52000000-1000 {
			opp-microvolt = <1000000 1000000 1350000>;
			opp-hz = /bits/ 64 <52000000>;
			opp-supported-hw = <0x000F>;
			required-opps = <&core_opp_1000>;
		};

		opp-60000000-1050 {
			opp-microvolt = <1050000 1050000 1350000>;
			opp-hz = /bits/ 64 <60000000>;
			opp-supported-hw = <0x000F>;
			required-opps = <&core_opp_1050>;
		};

		opp-100000000-1200 {
			opp-microvolt = <1200000 1200000 1350000>;
			opp-hz = /bits/ 64 <100000000>;
			opp-supported-hw = <0x000F>;
			required-opps = <&core_opp_1200>;
		};
	};

	sbc2_dvfs_opp_table: opp-table-sbc2 {
		compatible = "operating-points-v2";

		opp-52000000-1000 {
			opp-microvolt = <1000000 1000000 1350000>;
			opp-hz = /bits/ 64 <52000000>;
			opp-supported-hw = <0x000F>;
			required-opps = <&core_opp_1000>;
		};

		opp-60000000-1050 {
			opp-microvolt = <1050000 1050000 1350000>;
			opp-hz = /bits/ 64 <60000000>;
			opp-supported-hw = <0x000F>;
			required-opps = <&core_opp_1050>;
		};

		opp-100000000-1200 {
			opp-microvolt = <1200000 1200000 1350000>;
			opp-hz = /bits/ 64 <100000000>;
			opp-supported-hw = <0x000F>;
			required-opps = <&core_opp_1200>;
		};
	};

	sbc3_dvfs_opp_table: opp-table-sbc3 {
		compatible = "operating-points-v2";

		opp-52000000-1000 {
			opp-microvolt = <1000000 1000000 1350000>;
			opp-hz = /bits/ 64 <52000000>;
			opp-supported-hw = <0x000F>;
			required-opps = <&core_opp_1000>;
		};

		opp-60000000-1050 {
			opp-microvolt = <1050000 1050000 1350000>;
			opp-hz = /bits/ 64 <60000000>;
			opp-supported-hw = <0x000F>;
			required-opps = <&core_opp_1050>;
		};

		opp-100000000-1200 {
			opp-microvolt = <1200000 1200000 1350000>;
			opp-hz = /bits/ 64 <100000000>;
			opp-supported-hw = <0x000F>;
			required-opps = <&core_opp_1200>;
		};
	};

	sbc4_dvfs_opp_table: opp-table-sbc4 {
		compatible = "operating-points-v2";

		opp-52000000-1000 {
			opp-microvolt = <1000000 1000000 1350000>;
			opp-hz = /bits/ 64 <52000000>;
			opp-supported-hw = <0x000F>;
			required-opps = <&core_opp_1000>;
		};

		opp-60000000-1050 {
			opp-microvolt = <1050000 1050000 1350000>;
			opp-hz = /bits/ 64 <60000000>;
			opp-supported-hw = <0x000F>;
			required-opps = <&core_opp_1050>;
		};

		opp-100000000-1200 {
			opp-microvolt = <1200000 1200000 1350000>;
			opp-hz = /bits/ 64 <100000000>;
			opp-supported-hw = <0x000F>;
			required-opps = <&core_opp_1200>;
		};
	};

	sbc5_dvfs_opp_table: opp-table-sbc5 {
		compatible = "operating-points-v2";

		opp-52000000-1000 {
			opp-microvolt = <1000000 1000000 1350000>;
			opp-hz = /bits/ 64 <52000000>;
			opp-supported-hw = <0x000F>;
			required-opps = <&core_opp_1000>;
		};

		opp-60000000-1050 {
			opp-microvolt = <1050000 1050000 1350000>;
			opp-hz = /bits/ 64 <60000000>;
			opp-supported-hw = <0x000F>;
			required-opps = <&core_opp_1050>;
		};

		opp-100000000-1200 {
			opp-microvolt = <1200000 1200000 1350000>;
			opp-hz = /bits/ 64 <100000000>;
			opp-supported-hw = <0x000F>;
			required-opps = <&core_opp_1200>;
		};
	};

	sbc6_dvfs_opp_table: opp-table-sbc6 {
		compatible = "operating-points-v2";

		opp-52000000-1000 {
			opp-microvolt = <1000000 1000000 1350000>;
			opp-hz = /bits/ 64 <52000000>;
			opp-supported-hw = <0x000F>;
			required-opps = <&core_opp_1000>;
		};

		opp-60000000-1050 {
			opp-microvolt = <1050000 1050000 1350000>;
			opp-hz = /bits/ 64 <60000000>;
			opp-supported-hw = <0x000F>;
			required-opps = <&core_opp_1050>;
		};

		opp-100000000-1200 {
			opp-microvolt = <1200000 1200000 1350000>;
			opp-hz = /bits/ 64 <100000000>;
			opp-supported-hw = <0x000F>;
			required-opps = <&core_opp_1200>;
		};
	};

	sdmmc1_dvfs_opp_table: opp-table-sdmmc1 {
		compatible = "operating-points-v2";

		opp-104000000-950 {
			opp-microvolt = <950000 950000 1350000>;
			opp-hz = /bits/ 64 <104000000>;
			opp-supported-hw = <0x000F>;
			required-opps = <&core_opp_950>;
		};

		opp-208000000-1200 {
			opp-microvolt = <1200000 1200000 1350000>;
			opp-hz = /bits/ 64 <208000000>;
			opp-supported-hw = <0x000F>;
			required-opps = <&core_opp_1200>;
		};
	};

	sdmmc3_dvfs_opp_table: opp-table-sdmmc3 {
		compatible = "operating-points-v2";

		opp-104000000-950 {
			opp-microvolt = <950000 950000 1350000>;
			opp-hz = /bits/ 64 <104000000>;
			opp-supported-hw = <0x000F>;
			required-opps = <&core_opp_950>;
		};

		opp-208000000-1200 {
			opp-microvolt = <1200000 1200000 1350000>;
			opp-hz = /bits/ 64 <208000000>;
			opp-supported-hw = <0x000F>;
			required-opps = <&core_opp_1200>;
		};
	};

	usbd_dvfs_opp_table: opp-table-usbd {
		compatible = "operating-points-v2";

		opp-480000000-1000 {
			opp-microvolt = <1000000 1000000 1350000>;
			opp-hz = /bits/ 64 <480000000>;
			opp-supported-hw = <0x000F>;
			required-opps = <&core_opp_1000>;
		};
	};

	usb2_dvfs_opp_table: opp-table-usb2 {
		compatible = "operating-points-v2";

		opp-480000000-1000 {
			opp-microvolt = <1000000 1000000 1350000>;
			opp-hz = /bits/ 64 <480000000>;
			opp-supported-hw = <0x000F>;
			required-opps = <&core_opp_1000>;
		};
	};

	usb3_dvfs_opp_table: opp-table-usb3 {
		compatible = "operating-points-v2";

		opp-480000000-1000 {
			opp-microvolt = <1000000 1000000 1350000>;
			opp-hz = /bits/ 64 <480000000>;
			opp-supported-hw = <0x000F>;
			required-opps = <&core_opp_1000>;
		};
	};
};
